# BL123 register map
Vendor: BayLibre; File version: 1.0
Test SoC, for framework and application testing
CPU: other r1p0, little endian, no MPU, no FPU, 0 interrupt priority bits
Registers are 32-bit, read-write, no defined reset value unless marked. A register's access mark holds for its fields unless they carry their own. Offsets are from the block's base; lines under a group give offsets from that group; [hi:lo] are bit positions; {n}, {i} and the like mark numbered series; 'fields as' and 'values as' point back to an identical list; <NAME> marks a mode.

## Memory map
0x40000000 CLOCK0 size 0x100 — Clock module
0x40010000 PMU0 size 0x1000 — CPU PMU

## CLOCK0 — Clock module
Base 0x40000000
{0x0+3i} OSC{i} (i=0..2) — OSC{i} Register
  [31] EN — Enable
    0=Disable (OSC%s is disabled and does not operate); 1=Enable (OSC%s is enabled and can operate)
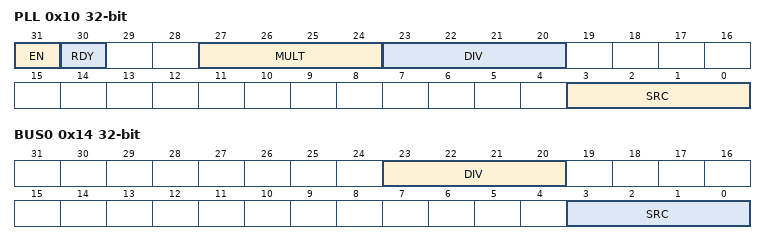
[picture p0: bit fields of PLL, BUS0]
0x10 PLL
  [31] EN — Enable
    0=Disable (PLL is disabled and does not operate); 1=Enable (PLL is enabled and can operate)
  [30] RDY — Ready
    0=Disabled (PLL is disabled and does not operate); 1=Ready (PLL is enabled and operate)
  [27:24] MULT — PLL multiplier
  [23:20] DIV — PLL divider
  [3:0] SRC — PLL source
    0=OSC0 (Select OSC0 as PLL source.); 1=OSC1 (Select OSC1 as PLL source.); 2=OSC2 (Select OSC2 as PLL source.)
0x14 BUS0 — BUS0 clock Register
  [23:20] DIV — BUS0 divider
  [3:0] SRC — BUS0 source
    0=OSC0 (Select OSC0 as PLL source.); 1=OSC1 (Select OSC1 as PLL source.); 2=OSC2 (Select OSC2 as PLL source.); 3=PLL (Select PLL as BUS0 source.)
0x18 BUS1 — BUS1 clock Register
  [23:20] DIV — BUS1 divider
{0x20+3i} GPIO{i} (i=0..2) — GPIO{i} clock Register
  [31] EN — Enable
    0=Disable (GPIO%s is disabled and does not operate); 1=Enable (GPIO%s is enabled and can operate)
{0x20+3i} UART{i} (i=0..2) — UART{i} clock Register
  [31] EN — Enable
    0=Disable (UART%s is disabled and does not operate); 1=Enable (UART%s is enabled and can operate)

## PMU0 — CPU PMU
Base 0x40010000
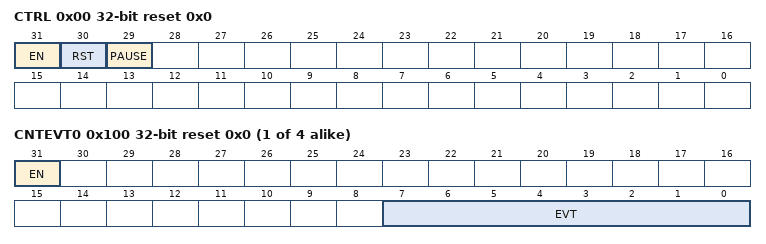
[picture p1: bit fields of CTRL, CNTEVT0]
0x00 CTRL reset 0x0
  [31] EN, [30] RST, [29] PAUSE
{0x100+4i} CNTEVT{i} (i=0..3) reset 0x0 — CNTEVT{i} Register
  [31] EN, [7:0] EVT
{0x120+4i} CNT{i} (i=0..3) reset 0x0 — CNT{i} Register

## Licence text in the file
MIT LIcense, Copyright (c) 2018 BayLibre
